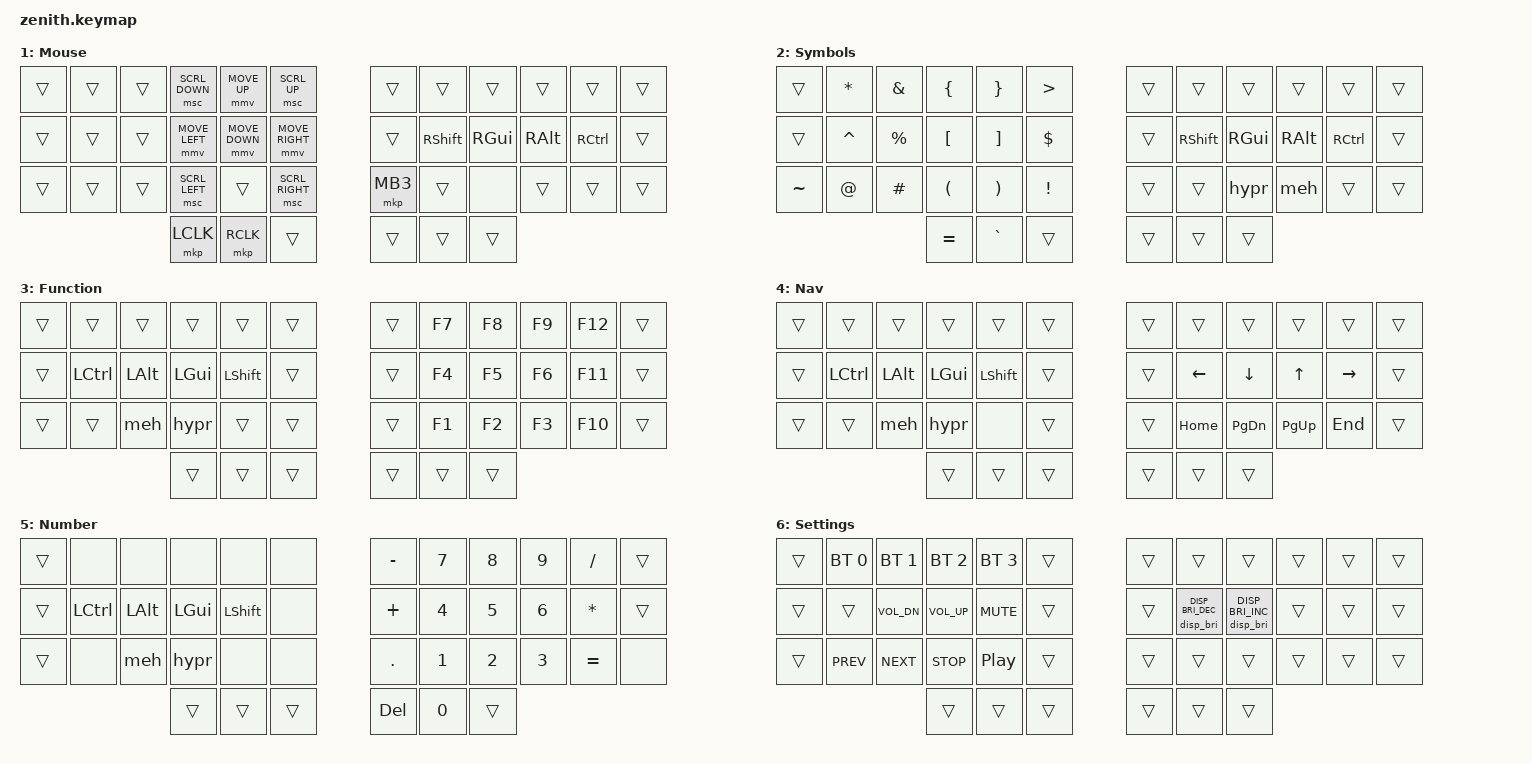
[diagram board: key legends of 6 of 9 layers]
//
//                                                        ▀▀▀▀▀     ▀▀▀▀▀          ▀▀█▀▀
//                                                        ▄▀▀▀▄  ▄  ▄▀▀▀▄  ▄  ▄▀▀▀▄  █  ▄▀▀▀▄
//                                                        █   █  █  █   █  █  █   █  █  █   █
//                                                         ▀▀▀   █   ▀▀▀   █   ▀▀▀   ▀   ▀▀▀
//                                                               █      ▄▄▄█▄▄▄    █   █
//                                                               ▀      █  █  █     █▄█
//                                                             ▀▀▀▀▀    █  █  █      ▀
//                                                                      ▀  ▀  ▀
//

#include <behaviors.dtsi>
#include <dt-bindings/zmk/keys.h>
#include <dt-bindings/zmk/bt.h>
#include <dt-bindings/zmk/outputs.h>
#include <dt-bindings/zmk/mouse.h>
#include <dt-bindings/zmk/display_brightness.h>

#define DEFAULT 0
#define MOUSE 1
#define SYMBOLS 2
#define FUNCTION 3
#define NAV 4
#define NUMBER 5
#define SETTINGS 6
#define FOCAL 7
#define ENTHIUM 8

// Zenith 42-key layout (3 rows x 12 cols + 6 thumbs):
//  0  1  2  3  4  5 |  6  7  8  9 10 11
// 12 13 14 15 16 17 | 18 19 20 21 22 23
// 24 25 26 27 28 29 | 30 31 32 33 34 35
//       36 37 38    | 39 40 41
// Outer pinky extras (vs Totem): pos 0, 11, 12, 23

#define KEYS_L 0 1 2 3 4 5 12 13 14 15 16 17 24 25 26 27 28 29
#define KEYS_R 6 7 8 9 10 11 18 19 20 21 22 23 30 31 32 33 34 35
#define THUMBS_L 36 37 38
#define THUMBS_R 39 40 41
#define THUMBS 36 37 38 39 40 41

&caps_word {
    continue-list = <UNDERSCORE MINUS BACKSPACE DELETE>;
};

/ {
    behaviors {
        disp_bri: disp_bri {
            compatible = "zmk,behavior-display-brightness";
            #binding-cells = <2>;
        };

        hm_l_idx: hm_left_index {
            compatible = "zmk,behavior-hold-tap";
            label = "HM_LEFT_INDEX";
            #binding-cells = <2>;
            flavor = "balanced";
            tapping-term-ms = <180>;
            quick-tap-ms = <150>;
            require-prior-idle-ms = <125>;
            hold-trigger-key-positions = <KEYS_R THUMBS>;
            hold-trigger-on-release;
            bindings = <&kp>, <&kp>;
        };

        hm_r_idx: hm_right_index {
            compatible = "zmk,behavior-hold-tap";
            label = "HM_RIGHT_INDEX";
            #binding-cells = <2>;
            flavor = "balanced";
            tapping-term-ms = <180>;
            quick-tap-ms = <150>;
            require-prior-idle-ms = <125>;
            hold-trigger-key-positions = <KEYS_L THUMBS>;
            hold-trigger-on-release;
            bindings = <&kp>, <&kp>;
        };

        hm_l_mid: hm_left_middle {
            compatible = "zmk,behavior-hold-tap";
            label = "HM_LEFT_MIDDLE";
            #binding-cells = <2>;
            flavor = "balanced";
            tapping-term-ms = <230>;
            quick-tap-ms = <150>;
            require-prior-idle-ms = <125>;
            hold-trigger-key-positions = <KEYS_R THUMBS>;
            hold-trigger-on-release;
            bindings = <&kp>, <&kp>;
        };

        hm_r_mid: hm_right_middle {
            compatible = "zmk,behavior-hold-tap";
            label = "HM_RIGHT_MIDDLE";
            #binding-cells = <2>;
            flavor = "balanced";
            tapping-term-ms = <230>;
            quick-tap-ms = <150>;
            require-prior-idle-ms = <125>;
            hold-trigger-key-positions = <KEYS_L THUMBS>;
            hold-trigger-on-release;
            bindings = <&kp>, <&kp>;
        };

        hm_l_rng: hm_left_ring {
            compatible = "zmk,behavior-hold-tap";
            label = "HM_LEFT_RING";
            #binding-cells = <2>;
            flavor = "balanced";
            tapping-term-ms = <230>;
            quick-tap-ms = <150>;
            require-prior-idle-ms = <125>;
            hold-trigger-key-positions = <KEYS_R THUMBS>;
            hold-trigger-on-release;
            bindings = <&kp>, <&kp>;
        };

        hm_r_rng: hm_right_ring {
            compatible = "zmk,behavior-hold-tap";
            label = "HM_RIGHT_RING";
            #binding-cells = <2>;
            flavor = "balanced";
            tapping-term-ms = <230>;
            quick-tap-ms = <150>;
            require-prior-idle-ms = <125>;
            hold-trigger-key-positions = <KEYS_L THUMBS>;
            hold-trigger-on-release;
            bindings = <&kp>, <&kp>;
        };

        hm_l_pnk: hm_left_pinky {
            compatible = "zmk,behavior-hold-tap";
            label = "HM_LEFT_PINKY";
            #binding-cells = <2>;
            flavor = "balanced";
            tapping-term-ms = <260>;
            quick-tap-ms = <150>;
            require-prior-idle-ms = <125>;
            hold-trigger-key-positions = <KEYS_R THUMBS>;
            hold-trigger-on-release;
            bindings = <&kp>, <&kp>;
        };

        hm_r_pnk: hm_right_pinky {
            compatible = "zmk,behavior-hold-tap";
            label = "HM_RIGHT_PINKY";
            #binding-cells = <2>;
            flavor = "balanced";
            tapping-term-ms = <260>;
            quick-tap-ms = <150>;
            require-prior-idle-ms = <125>;
            hold-trigger-key-positions = <KEYS_L THUMBS>;
            hold-trigger-on-release;
            bindings = <&kp>, <&kp>;
        };

        meh: meh {
            compatible = "zmk,behavior-macro";
            label = "MEH";
            #binding-cells = <0>;
            bindings = <&kp LC(LA(LSHFT))>;
        };

        hypr: hyper {
            compatible = "zmk,behavior-macro";
            label = "HYPER";
            #binding-cells = <0>;
            bindings = <&kp LC(LA(LG(LSHFT)))>;
        };

        lt_esc: layer_tap_esc {
            compatible = "zmk,behavior-hold-tap";
            label = "LAYER_TAP_ESC";
            #binding-cells = <2>;
            flavor = "tap-preferred";
            tapping-term-ms = <180>;
            bindings = <&mo>, <&kp>;
        };

        lt_space: layer_tap_space {
            compatible = "zmk,behavior-hold-tap";
            label = "LAYER_TAP_SPACE";
            #binding-cells = <2>;
            flavor = "tap-preferred";
            tapping-term-ms = <180>;
            bindings = <&mo>, <&kp>;
        };

        lt_minus: layer_tap_minus {
            compatible = "zmk,behavior-hold-tap";
            label = "LAYER_TAP_MINUS";
            #binding-cells = <2>;
            flavor = "tap-preferred";
            tapping-term-ms = <235>;
            bindings = <&mo>, <&kp>;
        };
    };

    combos {
        compatible = "zmk,combos";
        global-quick-tap-ms = <75>;

        combo_symbols_tl {
            timeout-ms = <50>;
            key-positions = <1 2>;
            bindings = <&kp LT>;
            layers = <SYMBOLS>;
        };

        combo_symbols_bl {
            timeout-ms = <50>;
            key-positions = <25 26>;
            bindings = <&kp PIPE>;
            layers = <SYMBOLS>;
        };

        combo_settings_tl {
            timeout-ms = <50>;
            key-positions = <1 2>;
            bindings = <&bt BT_CLR>;
            layers = <SETTINGS>;
        };

        combo_settings_tr {
            timeout-ms = <50>;
            key-positions = <9 10>;
            bindings = <&bootloader>;
            layers = <SETTINGS>;
        };

        combo_copy {
            timeout-ms = <50>;
            key-positions = <27 28>;
            bindings = <&kp LG(C)>;
        };

        combo_paste {
            timeout-ms = <50>;
            key-positions = <28 29>;
            bindings = <&kp LG(V)>;
        };
    };

    keymap {
        compatible = "zmk,keymap";

        default_layer {
            display-name = "Base";
            bindings = <
&caps_word  &kp Q               &kp W               &kp E               &kp R                &kp T    &kp Y   &kp U                &kp I                &kp O                &kp P                   &kp BSLH
&mt LS(LA(LG(LCTRL))) TAB  &hm_l_pnk LCTRL A   &hm_l_rng LALT S    &hm_l_mid LGUI D    &hm_l_idx LSHFT F    &kp G    &kp H   &hm_r_idx RSHFT J    &hm_r_mid RGUI K     &hm_r_rng RALT L     &hm_r_pnk RCTRL SEMI    &mt RS(RA(RG(RCTRL))) SQT
&kp UNDER  &kp Z  &kp X             &kp C               &kp V                &kp B    &kp N   &kp M                &kp COMMA            &kp DOT              &kp FSLH                &lt_minus SETTINGS MINUS
                                                    &mo FUNCTION        &lt NUMBER ENTER     &lt_esc NAV ESC  &kp BSPC             &lt_space SYMBOLS SPACE  &mo MOUSE
            >;
        };

        mouse_layer {
            display-name = "Mouse";
            bindings = <
&trans  &trans  &trans  &msc SCRL_DOWN  &mmv MOVE_UP    &msc SCRL_UP       &trans    &trans     &trans    &trans    &trans     &trans
&trans  &trans  &trans  &mmv MOVE_LEFT  &mmv MOVE_DOWN  &mmv MOVE_RIGHT    &trans    &kp RSHFT  &kp RGUI  &kp RALT  &kp RCTRL  &trans
&trans  &trans  &trans  &msc SCRL_LEFT  &trans          &msc SCRL_RIGHT    &mkp MB3  &trans     &none     &trans    &trans     &trans
                        &mkp LCLK       &mkp RCLK       &trans             &trans    &trans     &trans
            >;
        };

        symbols_layer {
            display-name = "Symbols";
            bindings = <
&trans     &kp STAR   &kp AMPS   &kp LBRC   &kp RBRC   &kp GT      &trans  &trans     &trans    &trans    &trans     &trans
&trans     &kp CARET  &kp PRCNT  &kp LBKT   &kp RBKT   &kp DLLR    &trans  &kp RSHFT  &kp RGUI  &kp RALT  &kp RCTRL  &trans
&kp TILDE  &kp AT     &kp HASH   &kp LPAR   &kp RPAR   &kp EXCL    &trans  &trans     &hypr     &meh      &trans     &trans
                                 &kp EQUAL  &kp GRAVE  &trans      &trans  &trans     &trans
            >;
        };

        function_layer {
            display-name = "Function";
            bindings = <
&trans  &trans     &trans    &trans    &trans     &trans    &trans  &kp F7  &kp F8  &kp F9  &kp F12  &trans
&trans  &kp LCTRL  &kp LALT  &kp LGUI  &kp LSHFT  &trans    &trans  &kp F4  &kp F5  &kp F6  &kp F11  &trans
&trans  &trans     &meh      &hypr     &trans     &trans    &trans  &kp F1  &kp F2  &kp F3  &kp F10  &trans
                             &trans    &trans     &trans    &trans  &trans  &trans
            >;
        };

        navigation_layer {
            display-name = "Nav";
            bindings = <
&trans  &trans     &trans    &trans    &trans     &trans    &trans  &trans    &trans     &trans   &trans     &trans
&trans  &kp LCTRL  &kp LALT  &kp LGUI  &kp LSHFT  &trans    &trans  &kp LEFT  &kp DOWN   &kp UP   &kp RIGHT  &trans
&trans  &trans     &meh      &hypr     &none      &trans    &trans  &kp HOME  &kp PG_DN  &kp PG_UP &kp END   &trans
                             &trans    &trans     &trans    &trans  &trans    &trans
            >;
        };

        number_layer {
            display-name = "Number";
            bindings = <
&trans  &none      &none     &none     &none      &none     &kp MINUS  &kp N7  &kp N8  &kp N9  &kp FSLH   &trans
&trans  &kp LCTRL  &kp LALT  &kp LGUI  &kp LSHFT  &none     &kp PLUS   &kp N4  &kp N5  &kp N6  &kp STAR   &trans
&trans  &none      &meh      &hypr     &none      &none     &kp DOT    &kp N1  &kp N2  &kp N3  &kp EQUAL  &none
                             &trans    &trans     &trans    &kp DEL    &kp N0  &trans
            >;
        };

        settings_layer {
            display-name = "Settings";
            bindings = <
&trans  &bt BT_SEL 0  &bt BT_SEL 1  &bt BT_SEL 2  &bt BT_SEL 3  &trans   &trans  &trans  &trans  &trans  &trans  &trans
&trans  &trans        &kp C_VOL_DN  &kp C_VOL_UP  &kp C_MUTE    &trans   &trans  &disp_bri DISP_BRI_DEC  &disp_bri DISP_BRI_INC  &trans  &trans  &trans
&trans  &kp C_PREV    &kp C_NEXT    &kp C_STOP    &kp C_PP      &trans   &trans  &trans  &trans  &trans  &trans  &trans
                                    &trans        &trans        &trans   &trans  &trans  &trans
            >;
        };

        focal_layer {
            display-name = "Focal";
            bindings = <
&caps_word  &kp V               &kp L               &kp H               &kp G                &kp K    &kp Q   &kp F                &kp O                &kp U                &kp J                    &kp BSLH
&mt LS(LA(LG(LCTRL))) TAB  &hm_l_pnk LCTRL S   &hm_l_rng LALT R    &hm_l_mid LGUI N    &hm_l_idx LSHFT T    &kp B    &kp Y   &hm_r_idx RSHFT C    &hm_r_mid RGUI A     &hm_r_rng RALT E     &hm_r_pnk RCTRL I        &mt RS(RA(RG(RCTRL))) FSLH
&kp UNDER  &kp Z  &kp X             &kp M               &kp D                &kp P    &kp SQT &kp W                &kp DOT              &kp SEMI             &kp COMMA                &lt_minus SETTINGS MINUS
                                                    &mo FUNCTION        &lt NUMBER ENTER     &lt_esc NAV ESC  &kp BSPC             &lt_space SYMBOLS SPACE  &mo MOUSE
            >;
        };

        enthium_layer {
            display-name = "Enthium";
            bindings = <
&caps_word  &kp Q               &kp W               &kp E               &kp R                &kp T    &kp Y   &kp U                &kp I                &kp O                &kp P                   &kp BSLH
&mt LS(LA(LG(LCTRL))) TAB  &hm_l_pnk LCTRL A   &hm_l_rng LALT S    &hm_l_mid LGUI D    &hm_l_idx LSHFT F    &kp G    &kp H   &hm_r_idx RSHFT J    &hm_r_mid RGUI K     &hm_r_rng RALT L     &hm_r_pnk RCTRL SEMI    &mt RS(RA(RG(RCTRL))) SQT
&kp UNDER  &kp Z  &kp X             &kp C               &kp V                &kp B    &kp N   &kp M                &kp COMMA            &kp DOT              &kp FSLH                &lt_minus SETTINGS MINUS
                                                    &mo FUNCTION        &lt NUMBER ENTER     &lt_esc NAV ESC  &kp BSPC             &lt_space SYMBOLS SPACE  &mo MOUSE
            >;
        };
    };
};
